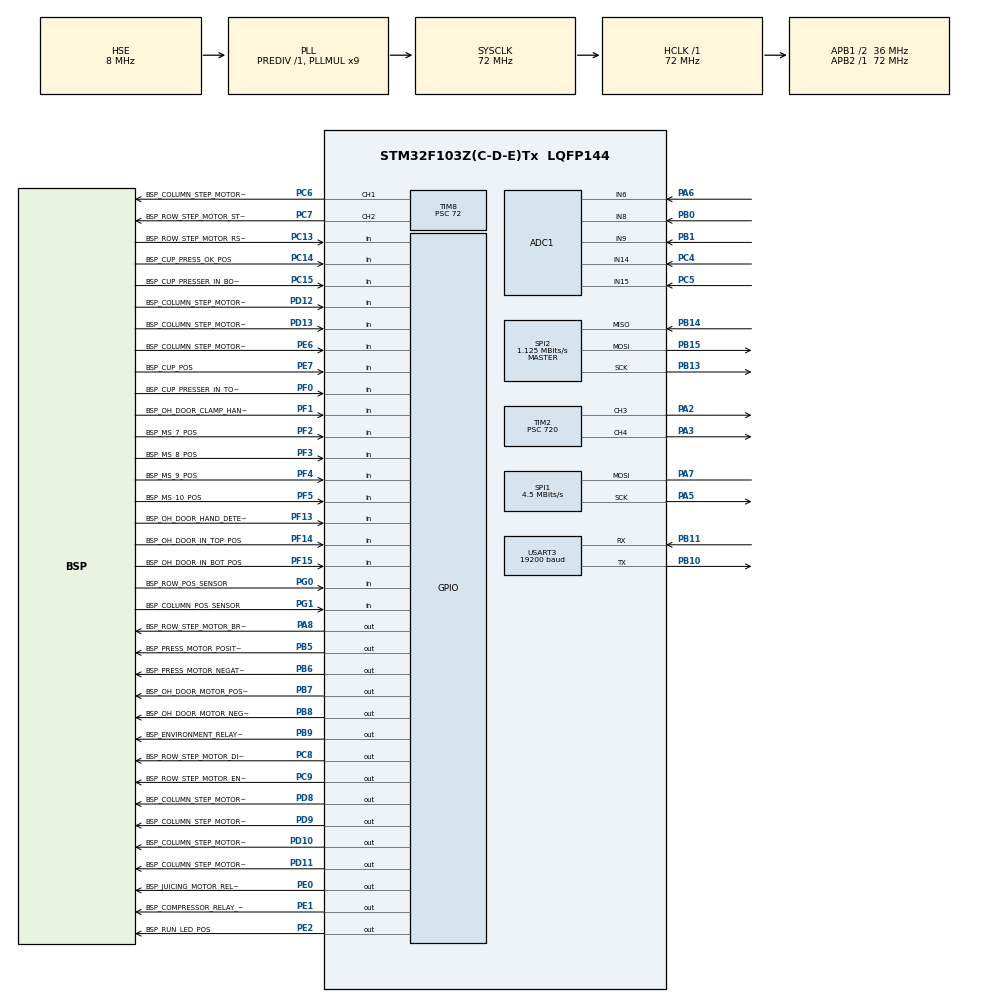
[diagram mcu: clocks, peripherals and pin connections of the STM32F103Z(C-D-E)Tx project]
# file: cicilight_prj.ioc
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ADC1.Channel-0\#ChannelRegularConversion=ADC_CHANNEL_6
ADC1.Channel-5\#ChannelRegularConversion=ADC_CHANNEL_8
ADC1.Channel-6\#ChannelRegularConversion=ADC_CHANNEL_9
ADC1.Channel-7\#ChannelRegularConversion=ADC_CHANNEL_14
ADC1.Channel-8\#ChannelRegularConversion=ADC_CHANNEL_15
ADC1.ContinuousConvMode=DISABLE
ADC1.DataAlign=ADC_DATAALIGN_RIGHT
ADC1.DiscontinuousConvMode=DISABLE
ADC1.EnableAnalogWatchDog=false
ADC1.EnableRegularConversion=ENABLE
ADC1.ExternalTrigConv=ADC_SOFTWARE_START
ADC1.InjNumberOfConversion=0
ADC1.NbrOfConversion=5
ADC1.NbrOfConversionFlag=1
ADC1.Rank-0\#ChannelRegularConversion=1
ADC1.Rank-5\#ChannelRegularConversion=2
ADC1.Rank-6\#ChannelRegularConversion=3
ADC1.Rank-7\#ChannelRegularConversion=4
ADC1.Rank-8\#ChannelRegularConversion=5
ADC1.SamplingTime-0\#ChannelRegularConversion=ADC_SAMPLETIME_28CYCLES_5
ADC1.SamplingTime-5\#ChannelRegularConversion=ADC_SAMPLETIME_28CYCLES_5
ADC1.SamplingTime-6\#ChannelRegularConversion=ADC_SAMPLETIME_28CYCLES_5
ADC1.SamplingTime-7\#ChannelRegularConversion=ADC_SAMPLETIME_28CYCLES_5
ADC1.SamplingTime-8\#ChannelRegularConversion=ADC_SAMPLETIME_28CYCLES_5
ADC1.ScanConvMode=ADC_SCAN_ENABLE
ADC1.master=1
Dma.ADC1.0.Direction=DMA_PERIPH_TO_MEMORY
Dma.ADC1.0.Instance=DMA1_Channel1
Dma.ADC1.0.MemDataAlignment=DMA_MDATAALIGN_HALFWORD
Dma.ADC1.0.MemInc=DMA_MINC_ENABLE
Dma.ADC1.0.Mode=DMA_CIRCULAR
Dma.ADC1.0.PeriphDataAlignment=DMA_PDATAALIGN_HALFWORD
Dma.ADC1.0.PeriphInc=DMA_PINC_DISABLE
Dma.ADC1.0.Priority=DMA_PRIORITY_LOW
Dma.Request0=ADC1
Dma.Request1=SPI1_TX
Dma.SPI1_TX.1.Direction=DMA_MEMORY_TO_PERIPH
Dma.SPI1_TX.1.Instance=DMA1_Channel3
Dma.SPI1_TX.1.MemDataAlignment=DMA_MDATAALIGN_BYTE
Dma.SPI1_TX.1.MemInc=DMA_MINC_ENABLE
Dma.SPI1_TX.1.Mode=DMA_NORMAL
Dma.SPI1_TX.1.PeriphDataAlignment=DMA_PDATAALIGN_BYTE
Dma.SPI1_TX.1.PeriphInc=DMA_PINC_DISABLE
Dma.SPI1_TX.1.Priority=DMA_PRIORITY_LOW
FREERTOS.INCLUDE_eTaskGetState=1
FREERTOS.INCLUDE_xEventGroupSetBitFromISR=1
FREERTOS.INCLUDE_xTaskGetCurrentTaskHandle=1
FREERTOS.INCLUDE_xTaskGetHandle=1
FREERTOS.INCLUDE_xTimerPendFunctionCall=1
FREERTOS.Tasks01=defaultTask,0,256,StartDefaultTask,Default,NULL,Dynamic,NULL,NULL
FREERTOS.configTIMER_TASK_PRIORITY=4
FREERTOS.configTOTAL_HEAP_SIZE=30720
FREERTOS.configUSE_MALLOC_FAILED_HOOK=1
FREERTOS.configUSE_TIMERS=1
Mcu.Family=STM32F1
Mcu.Name=STM32F103Z(C-D-E)Tx
Mcu.Package=LQFP144
NVIC.DMA1_Channel1_IRQn=true\:5\:0\:false\:false\:true\:true\:true
NVIC.DMA1_Channel3_IRQn=true\:5\:0\:false\:false\:true\:true\:true
NVIC.PriorityGroup=NVIC_PRIORITYGROUP_4
NVIC.USART3_IRQn=true\:5\:0\:true\:false\:true\:true\:true
OSC_IN.Mode=HSE-External-Oscillator
OSC_IN.Signal=RCC_OSC_IN
OSC_OUT.Mode=HSE-External-Oscillator
OSC_OUT.Signal=RCC_OSC_OUT
PA13.Mode=Serial_Wire
PA13.Signal=SYS_JTMS-SWDIO
PA14.Mode=Serial_Wire
PA14.Signal=SYS_JTCK-SWCLK
PA2.Signal=S_TIM2_CH3
PA3.Signal=S_TIM2_CH4
PA5.Mode=Simplex_Bidirectional_Master
PA5.Signal=SPI1_SCK
PA6.Signal=ADCx_IN6
PA7.Mode=Simplex_Bidirectional_Master
PA7.Signal=SPI1_MOSI
PA8.GPIO_Label=BSP_ROW_STEP_MOTOR_BRAKE_POS
PA8.Signal=GPIO_Output
PB0.Signal=ADCx_IN8
PB1.Signal=ADCx_IN9
PB10.Mode=Asynchronous
PB10.Signal=USART3_TX
PB11.Mode=Asynchronous
PB11.Signal=USART3_RX
PB13.Mode=Full_Duplex_Master
PB13.Signal=SPI2_SCK
PB14.GPIO_PuPd=GPIO_PULLUP
PB14.Mode=Full_Duplex_Master
PB14.Signal=SPI2_MISO
PB15.Mode=Full_Duplex_Master
PB15.Signal=SPI2_MOSI
PB5.GPIO_Label=BSP_PRESS_MOTOR_POSITIVE_RELAY_POS
PB5.Signal=GPIO_Output
PB6.GPIO_Label=BSP_PRESS_MOTOR_NEGATIVE_RELAY_POS
PB6.Signal=GPIO_Output
PB7.GPIO_Label=BSP_OH_DOOR_MOTOR_POSITIVE_RELAY_POS
PB7.Signal=GPIO_Output
PB8.GPIO_Label=BSP_OH_DOOR_MOTOR_NEGATIVE_RELAY_POS
PB8.Signal=GPIO_Output
PB9.GPIO_Label=BSP_ENVIRONMENT_RELAY_POS
PB9.Signal=GPIO_Output
PC13-TAMPER-RTC.GPIO_Label=BSP_ROW_STEP_MOTOR_RST_POS
PC13-TAMPER-RTC.Signal=GPIO_Input
PC14-OSC32_IN.GPIO_Label=BSP_CUP_PRESS_OK_POS
PC14-OSC32_IN.Signal=GPIO_Input
PC15-OSC32_OUT.GPIO_Label=BSP_CUP_PRESSER_IN_BOT_POS
PC15-OSC32_OUT.Signal=GPIO_Input
PC4.Signal=ADCx_IN14
PC5.Signal=ADCx_IN15
PC6.GPIO_Label=BSP_COLUMN_STEP_MOTOR_STEP_POS
PC6.Signal=S_TIM8_CH1
PC7.GPIO_Label=BSP_ROW_STEP_MOTOR_STEP_POS
PC7.Signal=S_TIM8_CH2
PC8.GPIO_Label=BSP_ROW_STEP_MOTOR_DIR_POS
PC8.Signal=GPIO_Output
PC9.GPIO_Label=BSP_ROW_STEP_MOTOR_EN_POS
PC9.Signal=GPIO_Output
PD10.GPIO_Label=BSP_COLUMN_STEP_MOTOR_RESET_POS
PD10.Signal=GPIO_Output
PD11.GPIO_Label=BSP_COLUMN_STEP_MOTOR_SLEEP_POS
PD11.Signal=GPIO_Output
PD12.GPIO_Label=BSP_COLUMN_STEP_MOTOR_FAULT_POS
PD12.GPIO_PuPd=GPIO_PULLUP
PD12.Signal=GPIO_Input
PD13.GPIO_Label=BSP_COLUMN_STEP_MOTOR_STALL_POS
PD13.GPIO_PuPd=GPIO_PULLUP
PD13.Signal=GPIO_Input
PD8.GPIO_Label=BSP_COLUMN_STEP_MOTOR_CS_POS
PD8.Signal=GPIO_Output
PD9.GPIO_Label=BSP_COLUMN_STEP_MOTOR_DIR_POS
PD9.Signal=GPIO_Output
PE0.GPIO_Label=BSP_JUICING_MOTOR_RELAY_POS
PE0.Signal=GPIO_Output
PE1.GPIO_Label=BSP_COMPRESSOR_RELAY_POS
PE1.Signal=GPIO_Output
PE2.GPIO_Label=BSP_RUN_LED_POS
PE2.Signal=GPIO_Output
PE6.GPIO_Label=BSP_COLUMN_STEP_MOTOR_RST_POS
PE6.Signal=GPIO_Input
PE7.GPIO_Label=BSP_CUP_POS
PE7.Signal=GPIO_Input
PF0.GPIO_Label=BSP_CUP_PRESSER_IN_TOP_POS
PF0.Signal=GPIO_Input
PF1.GPIO_Label=BSP_OH_DOOR_CLAMP_HAND_POS
PF1.Signal=GPIO_Input
PF13.GPIO_Label=BSP_OH_DOOR_HAND_DETECT_POS
PF13.Signal=GPIO_Input
PF14.GPIO_Label=BSP_OH_DOOR_IN_TOP_POS
PF14.Signal=GPIO_Input
PF15.GPIO_Label=BSP_OH_DOOR_IN_BOT_POS
PF15.Signal=GPIO_Input
PF2.GPIO_Label=BSP_MS_7_POS
PF2.Signal=GPIO_Input
PF3.GPIO_Label=BSP_MS_8_POS
PF3.Signal=GPIO_Input
PF4.GPIO_Label=BSP_MS_9_POS
PF4.Signal=GPIO_Input
PF5.GPIO_Label=BSP_MS_10_POS
PF5.Signal=GPIO_Input
PG0.GPIO_Label=BSP_ROW_POS_SENSOR
PG0.Signal=GPIO_Input
PG1.GPIO_Label=BSP_COLUMN_POS_SENSOR
PG1.Signal=GPIO_Input
ProjectManager.HeapSize=0x00
ProjectManager.StackSize=0x400
ProjectManager.TargetToolchain=MDK-ARM V5
RCC.ADCPresc=RCC_ADCPCLK2_DIV6
RCC.AHBFreq_Value=72000000
RCC.APB1CLKDivider=RCC_HCLK_DIV2
RCC.APB1Freq_Value=36000000
RCC.APB1TimFreq_Value=72000000
RCC.APB2Freq_Value=72000000
RCC.APB2TimFreq_Value=72000000
RCC.HCLKFreq_Value=72000000
RCC.PLLMUL=RCC_PLL_MUL9
RCC.PLLSourceVirtual=RCC_PLLSOURCE_HSE
RCC.SYSCLKFreq_VALUE=72000000
RCC.SYSCLKSource=RCC_SYSCLKSOURCE_PLLCLK
RCC.USBFreq_Value=72000000
SH.ADCx_IN14.0=ADC1_IN14,IN14
SH.ADCx_IN15.0=ADC1_IN15,IN15
SH.ADCx_IN6.0=ADC1_IN6,IN6
SH.ADCx_IN8.0=ADC1_IN8,IN8
SH.ADCx_IN9.0=ADC1_IN9,IN9
SH.S_TIM2_CH3.0=TIM2_CH3,PWM Generation3 CH3
SH.S_TIM2_CH4.0=TIM2_CH4,PWM Generation4 CH4
SH.S_TIM8_CH1.0=TIM8_CH1,PWM Generation1 CH1
SH.S_TIM8_CH2.0=TIM8_CH2,PWM Generation2 CH2
SPI1.BaudRatePrescaler=SPI_BAUDRATEPRESCALER_16
SPI1.CalculateBaudRate=4.5 MBits/s
SPI1.Direction=SPI_DIRECTION_1LINE
SPI1.Mode=SPI_MODE_MASTER
SPI1.VirtualType=VM_MASTER
SPI2.BaudRatePrescaler=SPI_BAUDRATEPRESCALER_32
SPI2.CalculateBaudRate=1.125 MBits/s
SPI2.Direction=SPI_DIRECTION_2LINES
SPI2.Mode=SPI_MODE_MASTER
SPI2.VirtualType=VM_MASTER
TIM2.Channel-PWM\ Generation3\ CH3=TIM_CHANNEL_3
TIM2.Channel-PWM\ Generation4\ CH4=TIM_CHANNEL_4
TIM2.Period=2000
TIM2.Prescaler=720
TIM8.Channel-PWM\ Generation1\ CH1=TIM_CHANNEL_1
TIM8.Channel-PWM\ Generation2\ CH2=TIM_CHANNEL_2
TIM8.Period=1000
TIM8.Prescaler=72
TIM8.Pulse-PWM\ Generation1\ CH1=40
TIM8.Pulse-PWM\ Generation2\ CH2=40
USART3.BaudRate=19200
USART3.VirtualMode=VM_ASYNC
VP_FREERTOS_VS_ENABLE.Mode=Enabled
board=cicilight_prj

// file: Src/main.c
/**
  ******************************************************************************
  * File Name          : main.c
  * Description        : Main program body
  ******************************************************************************
  * This notice applies to any and all portions of this file
  * that are not between comment pairs USER CODE BEGIN and
  * USER CODE END. Other portions of this file, whether
  * inserted by the user or by software development tools
  * are owned by their respective copyright owners.
  *
  * Copyright (c) 2018 STMicroelectronics International N.V.
  * All rights reserved.
  *
  * Redistribution and use in source and binary forms, with or without
  * modification, are permitted, provided that the following conditions are met:
  *
  * 1. Redistribution of source code must retain the above copyright notice,
  *    this list of conditions and the following disclaimer.
  * 2. Redistributions in binary form must reproduce the above copyright notice,
  *    this list of conditions and the following disclaimer in the documentation
  *    and/or other materials provided with the distribution.
  * 3. Neither the name of STMicroelectronics nor the names of other
  *    contributors to this software may be used to endorse or promote products
  *    derived from this software without specific written permission.
  * 4. This software, including modifications and/or derivative works of this
  *    software, must execute solely and exclusively on microcontroller or
  *    microprocessor devices manufactured by or for STMicroelectronics.
  * 5. Redistribution and use of this software other than as permitted under
  *    this license is void and will automatically terminate your rights under
  *    this license.
  *
  * THIS SOFTWARE IS PROVIDED BY STMICROELECTRONICS AND CONTRIBUTORS "AS IS"
  * AND ANY EXPRESS, IMPLIED OR STATUTORY WARRANTIES, INCLUDING, BUT NOT
  * LIMITED TO, THE IMPLIED WARRANTIES OF MERCHANTABILITY, FITNESS FOR A
  * PARTICULAR PURPOSE AND NON-INFRINGEMENT OF THIRD PARTY INTELLECTUAL PROPERTY
  * RIGHTS ARE DISCLAIMED TO THE FULLEST EXTENT PERMITTED BY LAW. IN NO EVENT
  * SHALL STMICROELECTRONICS OR CONTRIBUTORS BE LIABLE FOR ANY DIRECT, INDIRECT,
  * INCIDENTAL, SPECIAL, EXEMPLARY, OR CONSEQUENTIAL DAMAGES (INCLUDING, BUT NOT
  * LIMITED TO, PROCUREMENT OF SUBSTITUTE GOODS OR SERVICES; LOSS OF USE, DATA,
  * OR PROFITS; OR BUSINESS INTERRUPTION) HOWEVER CAUSED AND ON ANY THEORY OF
  * LIABILITY, WHETHER IN CONTRACT, STRICT LIABILITY, OR TORT (INCLUDING
  * NEGLIGENCE OR OTHERWISE) ARISING IN ANY WAY OUT OF THE USE OF THIS SOFTWARE,
  * EVEN IF ADVISED OF THE POSSIBILITY OF SUCH DAMAGE.
  *
  ******************************************************************************
  */

#include "main.h"
#include "stm32f1xx_hal.h"
#include "cmsis_os.h"
#include "adc.h"
#include "dma.h"
#include "spi.h"
#include "tim.h"
#include "usart.h"
#include "gpio.h"

/* USER CODE BEGIN PV */
/* Private variables ---------------------------------------------------------*/

/* USER CODE END PV */

void SystemClock_Config(void);
void MX_FREERTOS_Init(void);

/* USER CODE BEGIN PFP */
/* Private function prototypes -----------------------------------------------*/

/* USER CODE END PFP */

int main(void)
{

  /* MCU Configuration----------------------------------------------------------*/

  /* Reset of all peripherals, Initializes the Flash interface and the Systick. */
  HAL_Init();

  /* Configure the system clock */
  SystemClock_Config();

  /* Initialize all configured peripherals */
  MX_GPIO_Init();
  MX_DMA_Init();
  MX_TIM8_Init();
  MX_SPI2_Init();
  MX_TIM2_Init();
  MX_SPI1_Init();
  MX_ADC1_Init();
  MX_USART3_UART_Init();

  /* Call init function for freertos objects (in freertos.c) */
  MX_FREERTOS_Init();

  /* Start scheduler */
  osKernelStart();

  /* We should never get here as control is now taken by the scheduler */

  /* Infinite loop */
  while (1)
  {

  }

}

/** System Clock Configuration
*/
void SystemClock_Config(void)
{

  RCC_OscInitTypeDef RCC_OscInitStruct;
  RCC_ClkInitTypeDef RCC_ClkInitStruct;
  RCC_PeriphCLKInitTypeDef PeriphClkInit;

    /**Initializes the CPU, AHB and APB busses clocks
    */
  RCC_OscInitStruct.OscillatorType = RCC_OSCILLATORTYPE_HSE;
  RCC_OscInitStruct.HSEState = RCC_HSE_ON;
  RCC_OscInitStruct.HSEPredivValue = RCC_HSE_PREDIV_DIV1;
  RCC_OscInitStruct.HSIState = RCC_HSI_ON;
  RCC_OscInitStruct.PLL.PLLState = RCC_PLL_ON;
  RCC_OscInitStruct.PLL.PLLSource = RCC_PLLSOURCE_HSE;
  RCC_OscInitStruct.PLL.PLLMUL = RCC_PLL_MUL9;
  if (HAL_RCC_OscConfig(&RCC_OscInitStruct) != HAL_OK)
  {
    _Error_Handler(__FILE__, __LINE__);
  }

    /**Initializes the CPU, AHB and APB busses clocks
    */
  RCC_ClkInitStruct.ClockType = RCC_CLOCKTYPE_HCLK|RCC_CLOCKTYPE_SYSCLK
                              |RCC_CLOCKTYPE_PCLK1|RCC_CLOCKTYPE_PCLK2;
  RCC_ClkInitStruct.SYSCLKSource = RCC_SYSCLKSOURCE_PLLCLK;
  RCC_ClkInitStruct.AHBCLKDivider = RCC_SYSCLK_DIV1;
  RCC_ClkInitStruct.APB1CLKDivider = RCC_HCLK_DIV2;
  RCC_ClkInitStruct.APB2CLKDivider = RCC_HCLK_DIV1;

  if (HAL_RCC_ClockConfig(&RCC_ClkInitStruct, FLASH_LATENCY_2) != HAL_OK)
  {
    _Error_Handler(__FILE__, __LINE__);
  }

  PeriphClkInit.PeriphClockSelection = RCC_PERIPHCLK_ADC;
  PeriphClkInit.AdcClockSelection = RCC_ADCPCLK2_DIV6;
  if (HAL_RCCEx_PeriphCLKConfig(&PeriphClkInit) != HAL_OK)
  {
    _Error_Handler(__FILE__, __LINE__);
  }

    /**Configure the Systick interrupt time
    */
  HAL_SYSTICK_Config(HAL_RCC_GetHCLKFreq()/1000);

    /**Configure the Systick
    */
  HAL_SYSTICK_CLKSourceConfig(SYSTICK_CLKSOURCE_HCLK);

  /* SysTick_IRQn interrupt configuration */
  HAL_NVIC_SetPriority(SysTick_IRQn, 15, 0);
}

void _Error_Handler(char * file, int line)
{
  while(1)
  {
  }
}

/************************ (C) COPYRIGHT STMicroelectronics *****END OF FILE****/

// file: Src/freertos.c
/**
  ******************************************************************************
  * File Name          : freertos.c
  * Description        : Code for freertos applications
  ******************************************************************************
  * This notice applies to any and all portions of this file
  * that are not between comment pairs USER CODE BEGIN and
  * USER CODE END. Other portions of this file, whether
  * inserted by the user or by software development tools
  * are owned by their respective copyright owners.
  *
  * Copyright (c) 2018 STMicroelectronics International N.V.
  * All rights reserved.
  *
  * Redistribution and use in source and binary forms, with or without
  * modification, are permitted, provided that the following conditions are met:
  *
  * 1. Redistribution of source code must retain the above copyright notice,
  *    this list of conditions and the following disclaimer.
  * 2. Redistributions in binary form must reproduce the above copyright notice,
  *    this list of conditions and the following disclaimer in the documentation
  *    and/or other materials provided with the distribution.
  * 3. Neither the name of STMicroelectronics nor the names of other
  *    contributors to this software may be used to endorse or promote products
  *    derived from this software without specific written permission.
  * 4. This software, including modifications and/or derivative works of this
  *    software, must execute solely and exclusively on microcontroller or
  *    microprocessor devices manufactured by or for STMicroelectronics.
  * 5. Redistribution and use of this software other than as permitted under
  *    this license is void and will automatically terminate your rights under
  *    this license.
  *
  * THIS SOFTWARE IS PROVIDED BY STMICROELECTRONICS AND CONTRIBUTORS "AS IS"
  * AND ANY EXPRESS, IMPLIED OR STATUTORY WARRANTIES, INCLUDING, BUT NOT
  * LIMITED TO, THE IMPLIED WARRANTIES OF MERCHANTABILITY, FITNESS FOR A
  * PARTICULAR PURPOSE AND NON-INFRINGEMENT OF THIRD PARTY INTELLECTUAL PROPERTY
  * RIGHTS ARE DISCLAIMED TO THE FULLEST EXTENT PERMITTED BY LAW. IN NO EVENT
  * SHALL STMICROELECTRONICS OR CONTRIBUTORS BE LIABLE FOR ANY DIRECT, INDIRECT,
  * INCIDENTAL, SPECIAL, EXEMPLARY, OR CONSEQUENTIAL DAMAGES (INCLUDING, BUT NOT
  * LIMITED TO, PROCUREMENT OF SUBSTITUTE GOODS OR SERVICES; LOSS OF USE, DATA,
  * OR PROFITS; OR BUSINESS INTERRUPTION) HOWEVER CAUSED AND ON ANY THEORY OF
  * LIABILITY, WHETHER IN CONTRACT, STRICT LIABILITY, OR TORT (INCLUDING
  * NEGLIGENCE OR OTHERWISE) ARISING IN ANY WAY OUT OF THE USE OF THIS SOFTWARE,
  * EVEN IF ADVISED OF THE POSSIBILITY OF SUCH DAMAGE.
  *
  ******************************************************************************
  */

#include "FreeRTOS.h"
#include "task.h"
#include "cmsis_os.h"

/* USER CODE BEGIN Includes */
#include "gpio.h"
#include "tim.h"
#define APP_LOG_MODULE_NAME   "[freertos]"
#define APP_LOG_MODULE_LEVEL   APP_LOG_LEVEL_DEBUG
#include "app_log.h"

/* USER CODE END Includes */

osThreadId defaultTaskHandle;

void StartDefaultTask(void const * argument);

void MX_FREERTOS_Init(void); /* (MISRA C 2004 rule 8.1) */

/* Hook prototypes */
void vApplicationMallocFailedHook(void);

/* USER CODE BEGIN 5 */
__weak void vApplicationMallocFailedHook(void)
{
   /* vApplicationMallocFailedHook() will only be called if
   configUSE_MALLOC_FAILED_HOOK is set to 1 in FreeRTOSConfig.h. It is a hook
   function that will get called if a call to pvPortMalloc() fails.
   pvPortMalloc() is called internally by the kernel whenever a task, queue,
   timer or semaphore is created. It is also called by various parts of the
   demo application. If heap_1.c or heap_2.c are used, then the size of the
   heap available to pvPortMalloc() is defined by configTOTAL_HEAP_SIZE in
   FreeRTOSConfig.h, and the xPortGetFreeHeapSize() API function can be used
   to query the size of free heap space that remains (although it does not
   provide information on how the remaining heap might be fragmented). */
}
/* USER CODE END 5 */

/* Init FreeRTOS */

void MX_FREERTOS_Init(void) {

  /* Create the thread(s) */
  /* definition and creation of defaultTask */
  osThreadDef(defaultTask, StartDefaultTask, osPriorityNormal, 0, 256);
  defaultTaskHandle = osThreadCreate(osThread(defaultTask), NULL);

}

/* StartDefaultTask function */
void StartDefaultTask(void const * argument)
{

  /* USER CODE BEGIN StartDefaultTask */
  /* Infinite loop */
  void app_create_user_tasks(void);
  APP_LOG_DEBUG("等待系统上电完毕...\r\n");//24V�?12V上电可能不会同步，所�?
  osDelay(2000);//等待上电完毕
  app_create_user_tasks();
  for(;;)
  {
  osDelay(3000);
  }
  /* USER CODE END StartDefaultTask */
}

/************************ (C) COPYRIGHT STMicroelectronics *****END OF FILE****/
